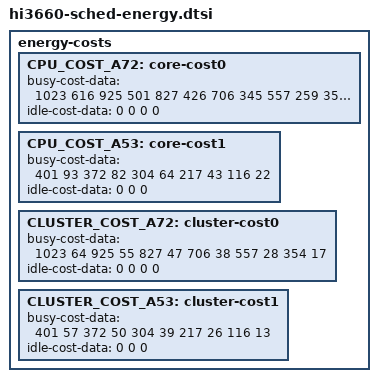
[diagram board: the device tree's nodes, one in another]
/*
 * Hikey960 dummy energy cost model data.
 *
 * XXX - This is inaccurate and needs work!
 *
 */


energy-costs {
	CPU_COST_A72: core-cost0 {
		busy-cost-data = <
			1023   616
			 925   501
			 827   426
			 706   345
			 557   259
			 354   156
		>;
		idle-cost-data = <
			0
			0
			0
			0
		>;
	};
	CPU_COST_A53: core-cost1 {
		busy-cost-data = <
			401   93
			372   82
			304   64
			217   43
			116   22
		>;
		idle-cost-data = <
			0
			0
			0
		>;
	};
	CLUSTER_COST_A72: cluster-cost0 {
		busy-cost-data = <
			1023   64
			 925   55
			 827   47
			 706   38
			 557   28
			 354   17
		>;
		idle-cost-data = <
			0
			0
			0
			0
		>;
	};
	CLUSTER_COST_A53: cluster-cost1 {
		busy-cost-data = <
			401   57
			372   50
			304   39
			217   26
			116   13
		>;
		idle-cost-data = <
			0
			0
			0
		>;
	};
};
